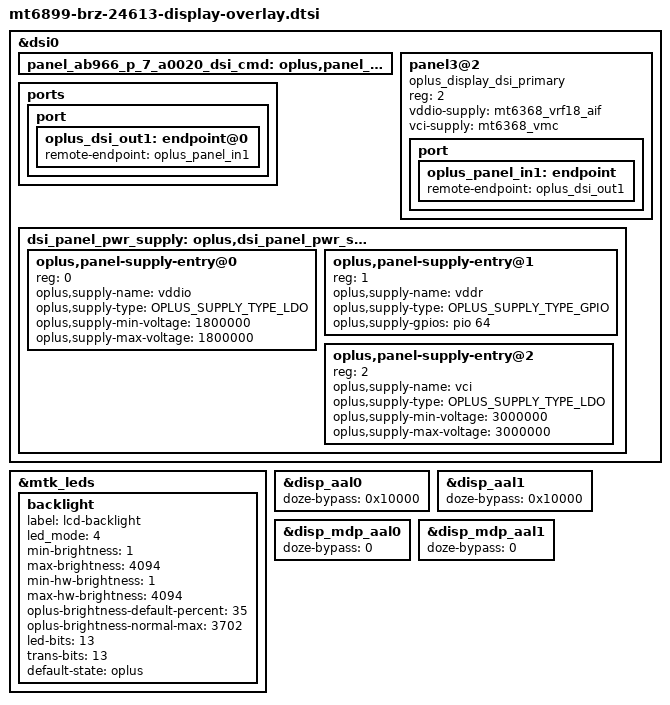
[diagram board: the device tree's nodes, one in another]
#include "mt6899-dsi-display-conf.h"
#include "panel-ab966-p-7-a0020-dsi-cmd-ext-params.dtsi"

&dsi0 {
	panel_ab966_p_7_a0020_dsi_cmd: oplus,panel_ab966_p_7_a0020_dsi_cmd {};
};

#include "panel-ab966-p-7-a0020-dsi-cmd.dtsi"

&mtk_leds {
	status = "okay";

	backlight {
		label = "lcd-backlight";
		led_mode = <4>;
		min-brightness = <1>;
		max-brightness = <4094>;
		min-hw-brightness = <1>;
		max-hw-brightness = <4094>;
		oplus-brightness-default-percent = <35>;
		oplus-brightness-normal-max = <3702>;
		led-bits = <13>;
		trans-bits = <13>;
		default-state = "oplus";
	};
};

&dsi0 {
	status = "okay";
	#address-cells = <1>;
	#size-cells = <0>;
	panel3@2 {
		compatible = "oplus_display_dsi_primary";
		reg = <2>;
		//1p2-gpios = <&pio 64 0>;
		vddio-supply = <&mt6368_vrf18_aif>;
		vci-supply = <&mt6368_vmc>;
		//rc-enable = <1>;
		pinctrl-names = "default";
		port {
			oplus_panel_in1: endpoint {
				remote-endpoint = <&oplus_dsi_out1>;
			};
		};
	};
	ports {
		port {
			oplus_dsi_out1: endpoint@0 {
				remote-endpoint = <&oplus_panel_in1>;
			};
		};
	};
};

&dsi0 {
	dsi_panel_pwr_supply: oplus,dsi_panel_pwr_supply {
		oplus,panel-supply-entry@0 {
			reg = <0>;
			oplus,supply-name = "vddio";
			oplus,supply-type = <OPLUS_SUPPLY_TYPE_LDO>;
			oplus,supply-min-voltage = <1800000>;
			oplus,supply-max-voltage = <1800000>;
		};
		oplus,panel-supply-entry@1 {
			reg = <1>;
			oplus,supply-name = "vddr";
			oplus,supply-type = <OPLUS_SUPPLY_TYPE_GPIO>;
			oplus,supply-gpios = <&pio 64 0>;
		};
		oplus,panel-supply-entry@2 {
			reg = <2>;
			oplus,supply-name = "vci";
			oplus,supply-type = <OPLUS_SUPPLY_TYPE_LDO>;
			oplus,supply-min-voltage = <3000000>;
			oplus,supply-max-voltage = <3000000>;
		};
	};
};

&disp_aal0 {
	doze-bypass = <0x10000>;
};

&disp_aal1 {
	doze-bypass = <0x10000>;
};

&disp_mdp_aal0 {
	doze-bypass = <0>;
};

&disp_mdp_aal1 {
        doze-bypass = <0>;
};
